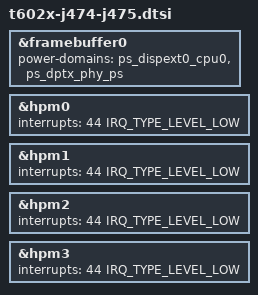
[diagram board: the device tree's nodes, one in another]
// SPDX-License-Identifier: GPL-2.0+ OR MIT
/*
 * Mac mini (M2 Pro, 2023) and Mac Studio (2023)
 *
 * This file contains the parts common to J474 and J475 devices with t6020,
 * t6021 and t6022.
 *
 * target-type: J474s / J475c / J475d
 *
 * Copyright The Asahi Linux Contributors
 */

/*
 * These models are very similar to the previous generation Mac Studio, other
 * than GPIO indices.
 */

#include "t600x-j375.dtsi"

&framebuffer0 {
	power-domains = <&ps_dispext0_cpu0>, <&ps_dptx_phy_ps>;
};

&hpm0 {
	interrupts = <44 IRQ_TYPE_LEVEL_LOW>;
};

&hpm1 {
	interrupts = <44 IRQ_TYPE_LEVEL_LOW>;
};

&hpm2 {
	interrupts = <44 IRQ_TYPE_LEVEL_LOW>;
};

&hpm3  {
	interrupts = <44 IRQ_TYPE_LEVEL_LOW>;
};
